# f28004x_dev_cfg_regs register map
Vendor: Texas Instruments
Peripheral module from a debugger description file (folder C2000).
Address unit: 16 bits
Registers are 32-bit, read-write, no defined reset value unless marked. A register's access mark holds for its fields unless they carry their own. Offsets are as the file gives them; lines under a group give offsets from that group; [hi:lo] are bit positions; {n}, {i} and the like mark numbered series; 'fields as' and 'values as' point back to an identical list; <NAME> marks a mode.

## DEV_CFG_REGS — DEV CFG Registers
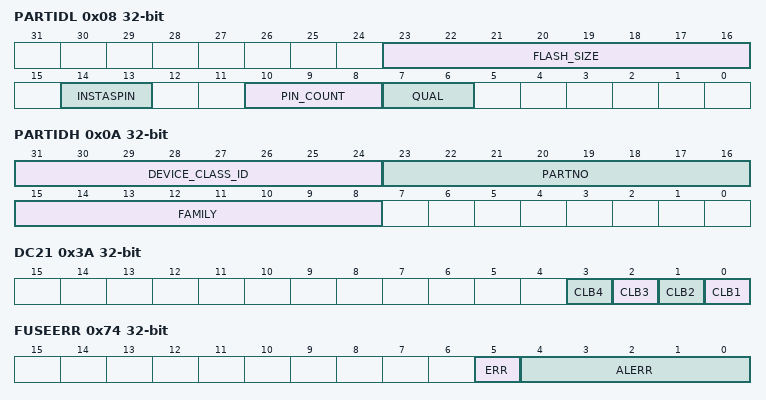
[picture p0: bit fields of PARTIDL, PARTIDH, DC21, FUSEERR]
0x08 PARTIDL — Lower 32-bit of Device PART Identification Number
  [23:16] FLASH_SIZE — Flash size in KB
  [14:13] INSTASPIN — Instaspin feature set
  [10:8] PIN_COUNT — Device Pin Count
  [7:6] QUAL — Qualification Status
0x0A PARTIDH access per field — Upper 32-bit of Device PART Identification Number
  [31:24] DEVICE_CLASS_ID ro
  [23:16] PARTNO rw — Device part number
  [15:8] FAMILY rw — Device family
0x0C REVID ro — Device Revision Number
  [15:0] REVID — Device Revision ID. This is specific to the Device
0x3A DC21 — Device Capability: CLB
  [n-1] CLB{n} (n=1..4) — CLB{n} Present
0x74 FUSEERR ro — e-Fuse error Status register
  [5] ERR — Efuse Self Test Error Status
  [4:0] ALERR — Efuse Autoload Error Status
0x82 SOFTPRES0 — Processing Block Software Reset register
  [0] CPU1_CLA1 — CPU1_CLA1 software reset bit
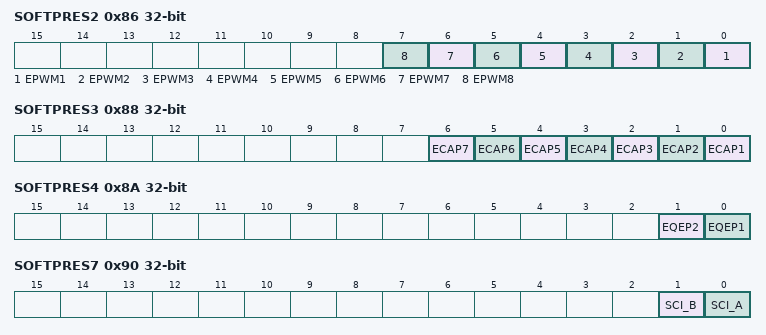
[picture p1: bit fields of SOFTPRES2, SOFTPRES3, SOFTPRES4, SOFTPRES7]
0x86 SOFTPRES2 — Peripheral Software Reset register
  [n-1] EPWM{n} (n=1..8) — EPWM{n} software reset bit
0x88 SOFTPRES3 — Peripheral Software Reset register
  [n-1] ECAP{n} (n=1..7) — ECAP{n} software reset bit
0x8A SOFTPRES4 — Peripheral Software Reset register
  [1] EQEP2 — EQEP2 software reset bit
  [0] EQEP1 — EQEP1 software reset bit
0x8E SOFTPRES6 — Peripheral Software Reset register
  [0] SD1 — SD1 software reset bit
0x90 SOFTPRES7 — Peripheral Software Reset register
  [1] SCI_B — SCI_B software reset bit
  [0] SCI_A — SCI_A software reset bit
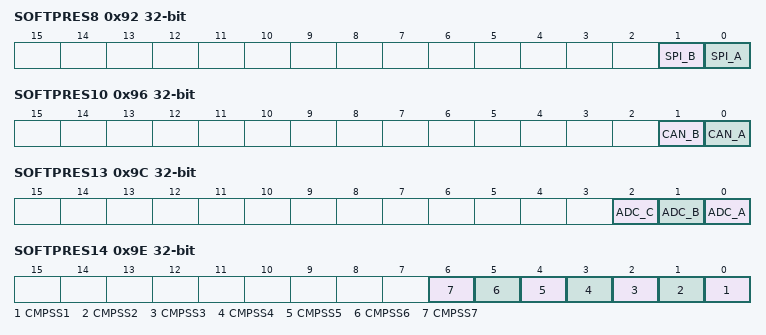
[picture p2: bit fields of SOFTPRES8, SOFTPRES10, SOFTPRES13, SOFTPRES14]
0x92 SOFTPRES8 — Peripheral Software Reset register
  [1] SPI_B — SPI_B software reset bit
  [0] SPI_A — SPI_A software reset bit
0x94 SOFTPRES9 — Peripheral Software Reset register
  [0] I2C_A — I2C_A software reset bit
0x96 SOFTPRES10 — Peripheral Software Reset register
  [1] CAN_B — CAN_B software reset bit
  [0] CAN_A — CAN_A software reset bit
0x9C SOFTPRES13 — Peripheral Software Reset register
  [2] ADC_C — ADC_C software reset bit
  [1] ADC_B — ADC_B software reset bit
  [0] ADC_A — ADC_A software reset bit
0x9E SOFTPRES14 — Peripheral Software Reset register
  [n-1] CMPSS{n} (n=1..7) — CMPSS{n} software reset bit
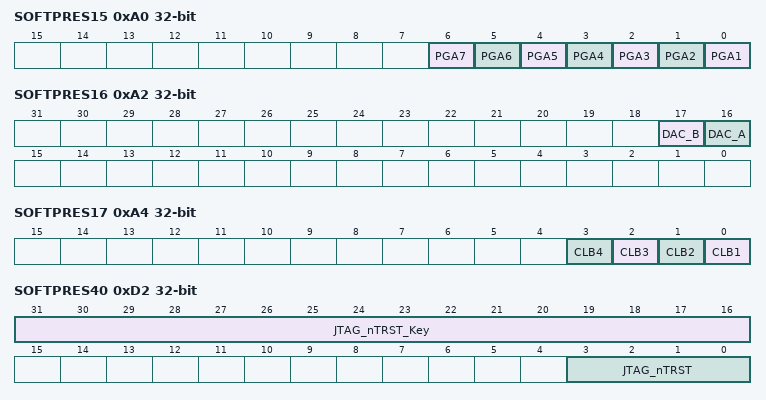
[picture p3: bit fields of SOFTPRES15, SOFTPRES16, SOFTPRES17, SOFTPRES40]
0xA0 SOFTPRES15 — Peripheral Software Reset register
  [n-1] PGA{n} (n=1..7) — PGA{n} software reset bit
0xA2 SOFTPRES16 — Peripheral Software Reset register
  [17] DAC_B — Buffered_DAC_B software reset bit
  [16] DAC_A — Buffered_DAC_A software reset bit
0xA4 SOFTPRES17 — Peripheral Software Reset register
  [n-1] CLB{n} (n=1..4) — CLB{n} software reset bit
0xA6 SOFTPRES18 access not given — Peripheral Software Reset register
0xA8 SOFTPRES19 — Peripheral Software Reset register
  [0] LIN_A — LIN_A software reset bit
0xAA SOFTPRES20 — Peripheral Software Reset register
  [0] PMBUS_A — PMBUS_A software reset bit
0xAC SOFTPRES21 access not given — Peripheral Software Reset register
0xD2 SOFTPRES40 — Peripheral Software Reset register
  [31:16] JTAG_nTRST_Key
  [3:0] JTAG_nTRST — Multi Bit JTAG nTRST
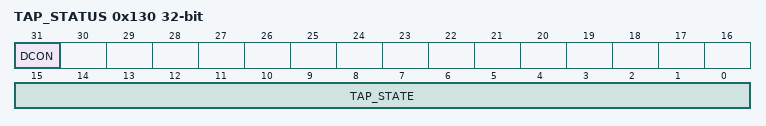
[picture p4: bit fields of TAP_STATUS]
0x130 TAP_STATUS ro — Status of JTAG State machine and Debugger Connect
  [31] DCON — Debugger Connect Indication
  [15:0] TAP_STATE — Present JTAG TAP State
